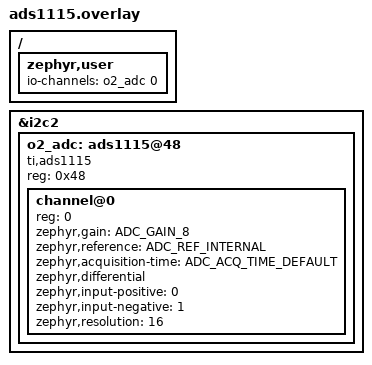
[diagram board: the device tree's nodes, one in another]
/*
 * O2 SENSOR BUILD: ADS1115 overlay. Build with o2.conf:
 *   west build -b thingy91x/nrf9151/ns -- -DEXTRA_CONF_FILE="secrets.conf;o2.conf" \
 *       -DEXTRA_DTC_OVERLAY_FILE=overlays/ads1115.overlay
 *
 * O2 INPUT: TI ADS1115 16-bit ADC on the Thingy's STEMMA QT / Qwiic
 * expansion port.
 *
 * On the Thingy:91 X, the internal I2C bus (i2c2: SCL P0.08, SDA P0.09)
 * reaches the expansion port through solder bridges SB8 (SCL) and SB9 (SDA)
 * and the TXS0102 level shifter (U24). SB8 and SB9 must be CLOSED.
 *
 * Use an ADS1115 breakout with a STEMMA QT / Qwiic connector and a
 * 4-pin JST-SH cable:
 *   cell (+) -> ADS1115 A0
 *   cell (-) -> ADS1115 A1, and to the ADS1115 GND
 *   ADDR     -> GND (address 0x48, the default on most breakouts)
 *
 * ADC_GAIN_8 = +/-256 mV full scale, 7.8 uV per step, for a raw galvanic
 * cell. For an amplified sensor use ADC_GAIN_1 (+/-2.048 V) or
 * ADC_GAIN_1_2 (+/-4.096 V, input must stay below the ADS1115 supply).
 *
 * P0.18 / P0.19 are also connected to these lines (EXP_BOARD PIN1/PIN2) when
 * SB8/SB9 are closed, so the firmware must leave them unused.
 */

#include <zephyr/dt-bindings/adc/adc.h>

/ {
	zephyr,user {
		io-channels = <&o2_adc 0>;
	};
};

&i2c2 {
	o2_adc: ads1115@48 {
		compatible = "ti,ads1115";
		reg = <0x48>;
		#io-channel-cells = <1>;
		#address-cells = <1>;
		#size-cells = <0>;
		status = "okay";

		channel@0 {
			reg = <0>;
			zephyr,gain = "ADC_GAIN_8";
			zephyr,reference = "ADC_REF_INTERNAL";
			zephyr,acquisition-time = <ADC_ACQ_TIME_DEFAULT>;
			zephyr,differential;
			zephyr,input-positive = <0>;
			zephyr,input-negative = <1>;
			zephyr,resolution = <16>;
		};
	};
};
